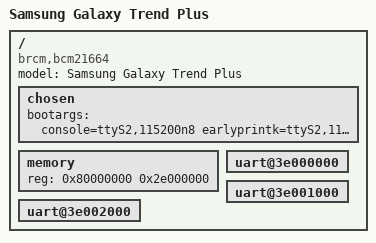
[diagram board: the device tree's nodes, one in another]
// SPDX-License-Identifier: GPL-2.0
/dts-v1/;

#include <dt-bindings/gpio/gpio.h>

#include "bcm21664.dtsi"

/ {
	model = "Samsung Galaxy Trend Plus";
	compatible = "brcm,bcm21664";

	chosen {
		bootargs = "console=ttyS2,115200n8 earlyprintk=ttyS2,115200,keep ignore_loglevel PMOS_NO_OUTPUT_REDIRECT";
	};

	memory {
		device_type = "memory";
		reg = <0x80000000 0x2e000000>; /* 736 MB */
	};

	uart@3e000000 {
		status="okay";
    	};

	uart@3e001000 {
		status="okay";
    	};

	uart@3e002000 {
		status="okay";
    	};
};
